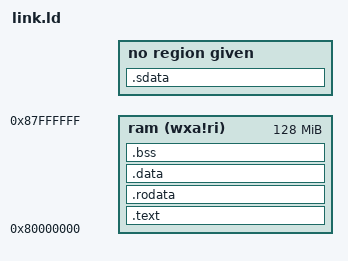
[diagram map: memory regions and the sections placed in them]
OUTPUT_ARCH( "riscv" )
ENTRY( _start )

MEMORY
{
  ram   (wxa!ri) : ORIGIN = 0x80000000, LENGTH = 128M
}

PHDRS
{
  text PT_LOAD;
  data PT_LOAD;
  bss PT_LOAD;
}

SECTIONS
{
  .text : {
    *(.text.start);
    PROVIDE(_text_start = .);
    *(.text.init) *(.text .text.*)
    PROVIDE(_text_end = .);
  } >ram AT>ram :text

  . = ALIGN(0x1000);
  etext = .;

  .sdata : {
    _gp = . + 0x800;
    *(.srodata.cst16) *(.srodata.cst8) *(.srodata.cst4) *(.srodata.cst2)
    *(.srodata*)
    *(.sdata .sdata.* .gnu.linkonce.s.*)
  }

  .rodata : {
    PROVIDE(_rodata_start = .);
    *(.rodata .rodata.*)
    PROVIDE(_rodata_end = .);
  } >ram AT>ram :text
  

  .data : {
    . = ALIGN(4096);
    PROVIDE(_data_start = .);
    *(.sdata .sdata.*) *(.data .data.*)
    PROVIDE(_data_end = .);
  } >ram AT>ram :data

  .bss :{
    PROVIDE(_bss_start = .);
    *(.sbss .sbss.*) *(.bss .bss.*)
    PROVIDE(_bss_end = .);
  } >ram AT>ram :bss

  PROVIDE(_memory_start = ORIGIN(ram));
  PROVIDE(_memory_end = ORIGIN(ram) + LENGTH(ram));
  . += 0x8000;
  stack_top = .;
  end = .;
}
